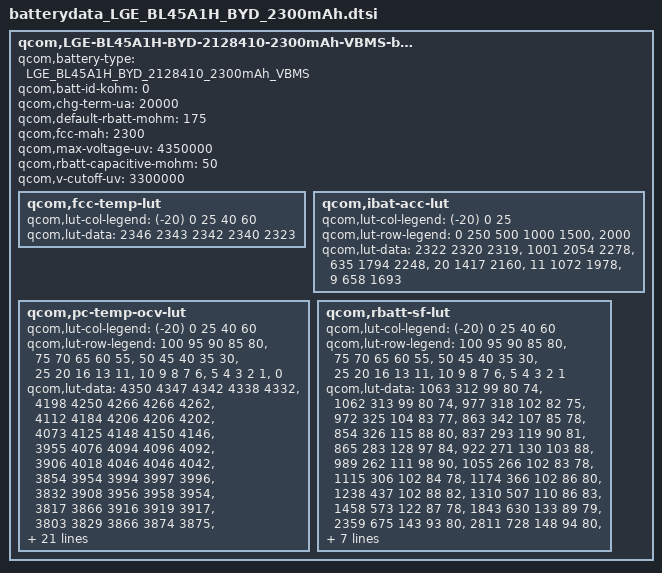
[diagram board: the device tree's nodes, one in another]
/* Copyright (c) 2015, The Linux Foundation. All rights reserved.
 *
 * This program is free software; you can redistribute it and/or modify
 * it under the terms of the GNU General Public License version 2 and
 * only version 2 as published by the Free Software Foundation.
 *
 * This program is distributed in the hope that it will be useful,
 * but WITHOUT ANY WARRANTY; without even the implied warranty of
 * MERCHANTABILITY or FITNESS FOR A PARTICULAR PURPOSE.  See the
 * GNU General Public License for more details.
 */
qcom,LGE-BL45A1H-BYD-2128410-2300mAh-VBMS-batterydata {
	qcom,battery-type = "LGE_BL45A1H_BYD_2128410_2300mAh_VBMS";
	qcom,batt-id-kohm = <0>;
	qcom,chg-term-ua = <20000>;
	qcom,default-rbatt-mohm = <175>;
	qcom,fcc-mah = <2300>;
	qcom,max-voltage-uv = <4350000>;
	qcom,rbatt-capacitive-mohm = <50>;
	qcom,v-cutoff-uv = <3300000>;

	qcom,fcc-temp-lut {
		qcom,lut-col-legend = <(-20) 0 25 40 60>;
		qcom,lut-data = <2346 2343 2342 2340 2323>;
	};

	qcom,ibat-acc-lut {
		qcom,lut-col-legend = <(-20) 0 25>;
		qcom,lut-row-legend = <0 250 500 1000 1500>,
					<2000>;
		qcom,lut-data = <2322 2320 2319>,
				<1001 2054 2278>,
				<635 1794 2248>,
				<20 1417 2160>,
				<11 1072 1978>,
				<9 658 1693>;
	};

	qcom,pc-temp-ocv-lut {
		qcom,lut-col-legend = <(-20) 0 25 40 60>;
		qcom,lut-row-legend = <100 95 90 85 80>,
					<75 70 65 60 55>,
					<50 45 40 35 30>,
					<25 20 16 13 11>,
					<10 9 8 7 6>,
					<5 4 3 2 1>,
					<0>;
		qcom,lut-data = <4350 4347 4342 4338 4332>,
				<4198 4250 4266 4266 4262>,
				<4112 4184 4206 4206 4202>,
				<4073 4125 4148 4150 4146>,
				<3955 4076 4094 4096 4092>,
				<3906 4018 4046 4046 4042>,
				<3854 3954 3994 3997 3996>,
				<3832 3908 3956 3958 3954>,
				<3817 3866 3916 3919 3917>,
				<3803 3829 3866 3874 3875>,
				<3788 3802 3831 3834 3834>,
				<3774 3793 3808 3810 3810>,
				<3759 3785 3789 3792 3792>,
				<3744 3776 3776 3778 3777>,
				<3730 3765 3769 3765 3762>,
				<3714 3748 3760 3752 3738>,
				<3696 3722 3740 3732 3718>,
				<3678 3696 3712 3706 3695>,
				<3660 3686 3684 3680 3670>,
				<3644 3680 3676 3672 3663>,
				<3634 3677 3674 3670 3661>,
				<3620 3674 3672 3669 3660>,
				<3606 3670 3669 3667 3658>,
				<3588 3665 3665 3664 3655>,
				<3566 3656 3660 3658 3648>,
				<3538 3636 3643 3641 3625>,
				<3504 3602 3602 3599 3582>,
				<3461 3550 3542 3533 3520>,
				<3397 3470 3458 3450 3436>,
				<3282 3342 3326 3314 3305>,
				<3000 3000 3000 3000 3000>;
	};

	qcom,rbatt-sf-lut {
		qcom,lut-col-legend = <(-20) 0 25 40 60>;
		qcom,lut-row-legend = <100 95 90 85 80>,
					<75 70 65 60 55>,
					<50 45 40 35 30>,
					<25 20 16 13 11>,
					<10 9 8 7 6>,
					<5 4 3 2 1>;
		qcom,lut-data = <1063 312 99 80 74>,
				<1062 313 99 80 74>,
				<977 318 102 82 75>,
				<972 325 104 83 77>,
				<863 342 107 85 78>,
				<854 326 115 88 80>,
				<837 293 119 90 81>,
				<865 283 128 97 84>,
				<922 271 130 103 88>,
				<989 262 111 98 90>,
				<1055 266 102 83 78>,
				<1115 306 102 84 78>,
				<1174 366 102 86 80>,
				<1238 437 102 88 82>,
				<1310 507 110 86 83>,
				<1458 573 122 87 78>,
				<1843 630 133 89 79>,
				<2359 675 143 93 80>,
				<2811 728 148 94 80>,
				<3048 760 147 94 80>,
				<3409 793 154 95 81>,
				<3842 827 163 99 82>,
				<4368 869 173 103 85>,
				<5041 916 186 105 86>,
				<5944 968 202 109 86>,
				<7248 1025 219 111 85>,
				<9124 1095 238 113 86>,
				<11872 1266 270 120 89>,
				<16374 1722 321 135 95>,
				<25713 2752 417 175 107>;
	};
};
